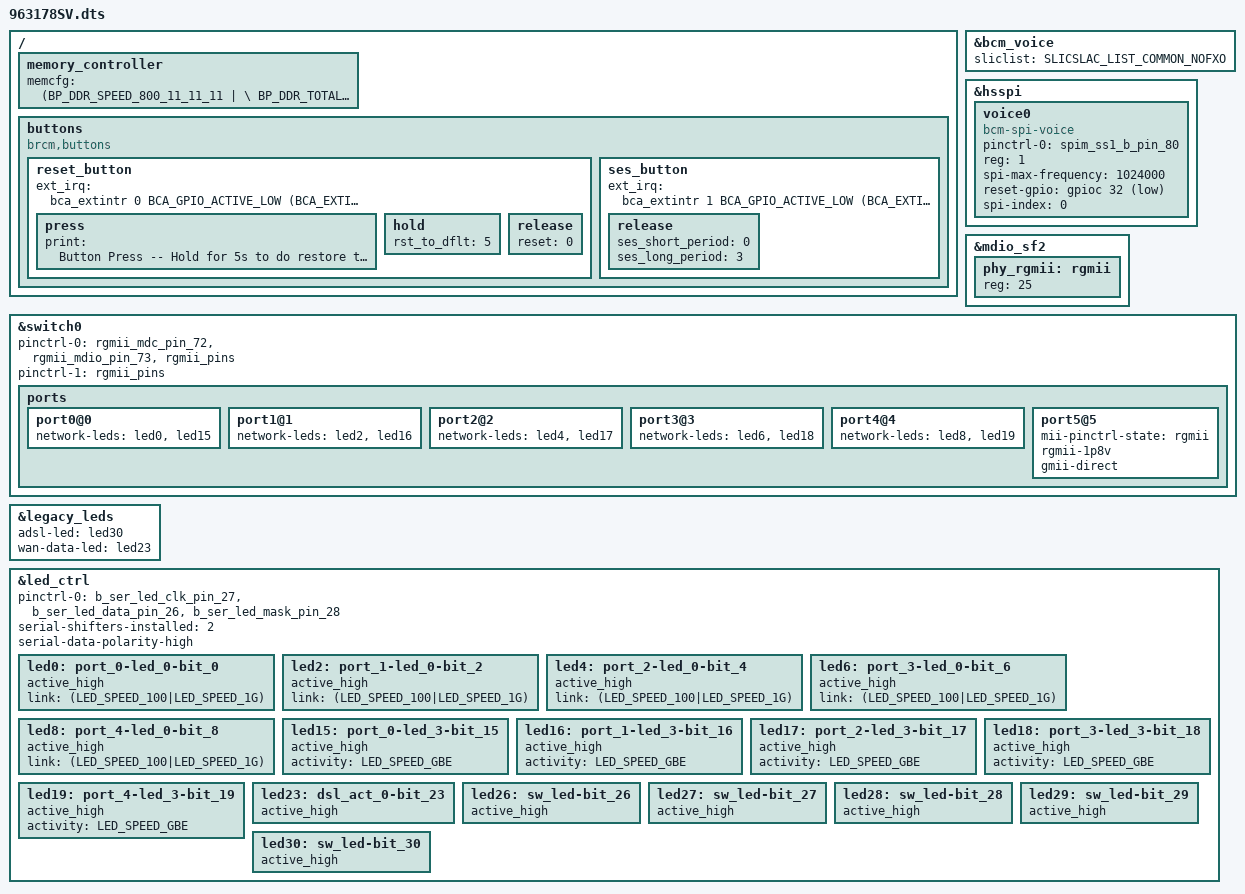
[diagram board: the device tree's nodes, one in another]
#include "63178.dtsi"
#include "../bcm_voice.dtsi"

/ {
    memory_controller {
        memcfg = <(BP_DDR_SPEED_800_11_11_11 | \
                   BP_DDR_TOTAL_SIZE_512MB   | \
                   BP_DDR_DEVICE_WIDTH_16    | \
                   BP_DDR_TOTAL_WIDTH_16BIT  | \
                   BP_DDR_63178_DEFAULT)>;
    };

	buttons {
		compatible = "brcm,buttons";
		reset_button {
			ext_irq = <&bca_extintr 0 BCA_GPIO_ACTIVE_LOW (BCA_EXTINTR_TYPE_LOW_LEVEL | BCA_EXTINTR_TYPE_SENSE_EDGE)>;
			press {
				print = "Button Press -- Hold for 5s to do restore to default";
			};
			hold {
				rst_to_dflt = <5>;
			};
			release {
				reset = <0>;
			};	
		};
		ses_button {
			ext_irq = <&bca_extintr 1 BCA_GPIO_ACTIVE_LOW (BCA_EXTINTR_TYPE_LOW_LEVEL | BCA_EXTINTR_TYPE_SENSE_EDGE)>;
			release {
				ses_short_period = <0>;
				ses_long_period = <3>;
			};
		};
	};
};
&bcm_voice{
	sliclist = SLICSLAC_LIST_COMMON_NOFXO;
 };

&hsspi {
	voice0 {
		pinctrl-0 = <&spim_ss1_b_pin_80>;
		pinctrl-names = "default";
		compatible = "bcm-spi-voice";
		reg = <1>; /* chip select 1 */
		spi-max-frequency = <1024000>;
		reset-gpio = <&gpioc 32 GPIO_ACTIVE_LOW>;
		spi-index = <0>;/* voice header index */
	};	
};
&mdio_sf2 {
	phy_rgmii: rgmii {
		reg = <25>;
		status = "okay";
	};
};

&switch0 {
	pinctrl-names = "default", "rgmii"; 
	pinctrl-0 = <&rgmii_mdc_pin_72 &rgmii_mdio_pin_73 &rgmii_pins>; 
	pinctrl-1 = <&rgmii_pins>; 

	ports {
		port0@0 {
			network-leds = <&led0 &led15>;
			status = "okay";
		};

		port1@1 {
			network-leds = <&led2 &led16>;
			status = "okay";
		};

		port2@2 {
			network-leds = <&led4 &led17>;
			status = "okay";
		};

		port3@3 {
			network-leds = <&led6 &led18>;
			status = "okay";
		};

		port4@4 {
			network-leds = <&led8 &led19>;
			status = "okay";
		};
		port5@5 {
			mii-pinctrl-state = "rgmii";
			rgmii-1p8v;
			gmii-direct;
			status = "okay";
		};
	};
};

&legacy_leds {
	adsl-led = <&led30>;
	wan-data-led = <&led23>;
};

&led_ctrl {
    pinctrl-names = "default";
    pinctrl-0 = <&b_ser_led_clk_pin_27 &b_ser_led_data_pin_26 &b_ser_led_mask_pin_28>;
    serial-shifters-installed = <2>;
    serial-data-polarity-high;
    led0: port_0-led_0-bit_0 {
        active_high;
        link = <(LED_SPEED_100|LED_SPEED_1G)>;
        status = "okay";
    };
    led2: port_1-led_0-bit_2 {
        active_high;
        link = <(LED_SPEED_100|LED_SPEED_1G)>;
        status = "okay";
    };
    led4: port_2-led_0-bit_4 {
        active_high;
        link = <(LED_SPEED_100|LED_SPEED_1G)>;
        status = "okay";
    };
    led6: port_3-led_0-bit_6 {
        active_high;
        link = <(LED_SPEED_100|LED_SPEED_1G)>;
        status = "okay";
    };
    led8: port_4-led_0-bit_8 {
        active_high;
        link = <(LED_SPEED_100|LED_SPEED_1G)>;
        status = "okay";
    };
    led15: port_0-led_3-bit_15 {
        active_high;
	activity = <LED_SPEED_GBE>;
        status = "okay";
    };
    led16: port_1-led_3-bit_16 {
        active_high;
	activity = <LED_SPEED_GBE>;
        status = "okay";
    };
    led17: port_2-led_3-bit_17 {
        active_high;
	activity = <LED_SPEED_GBE>;
        status = "okay";
    };
    led18: port_3-led_3-bit_18 {
        active_high;
	activity = <LED_SPEED_GBE>;
        status = "okay";
    };
    led19: port_4-led_3-bit_19 {
        active_high;
	activity = <LED_SPEED_GBE>;
        status = "okay";
    };
    led23: dsl_act_0-bit_23 {
        active_high;
        status = "okay";
    };
    led26: sw_led-bit_26 {
        active_high;
        status = "okay";
    };
    led27: sw_led-bit_27 {
        active_high;
        status = "okay";
    };
    led28: sw_led-bit_28 {
        active_high;
        status = "okay";
    };
    led29: sw_led-bit_29 {
        active_high;
        status = "okay";
    };
    led30: sw_led-bit_30 {
        active_high;
        status = "okay";
    };
};

